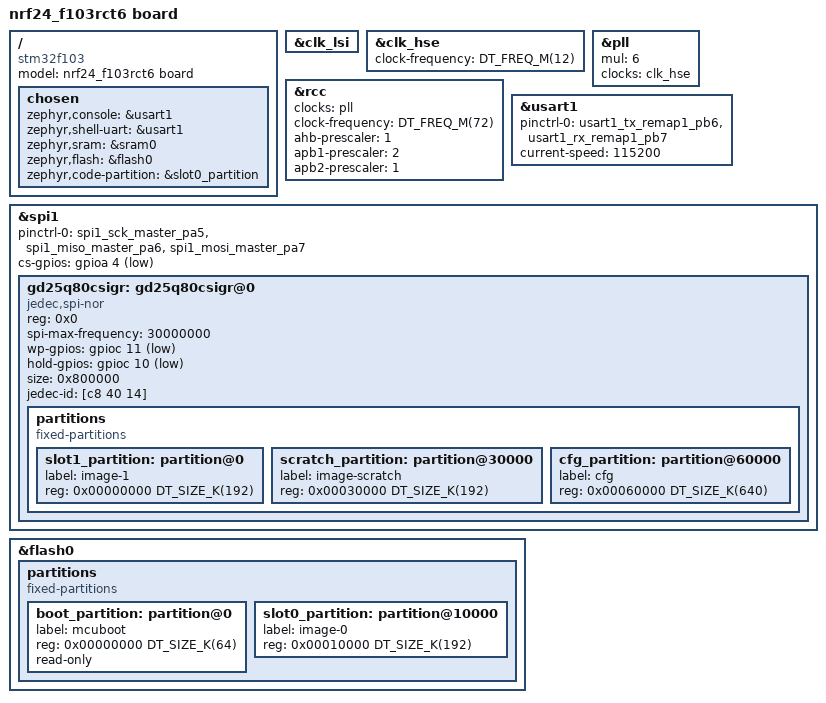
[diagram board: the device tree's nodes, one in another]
/*
 * Copyright (c) 2020 WuhanStudio
 *
 * SPDX-License-Identifier: Apache-2.0
 */

/dts-v1/;
#include <st/f1/stm32f103Xc.dtsi>
#include <st/f1/stm32f103r(c-d-e)tx-pinctrl.dtsi>

/ {
	model = "nrf24_f103rct6 board";
	compatible = "stm32f103";

	chosen {
		zephyr,console = &usart1;
		zephyr,shell-uart = &usart1;
		zephyr,sram = &sram0;
		zephyr,flash = &flash0;
		zephyr,code-partition = &slot0_partition;
	};
};

&clk_lsi {
	status = "okay";
};

&clk_hse {
	clock-frequency = <DT_FREQ_M(12)>;
	status = "okay";
};

&pll {
	mul = <6>;
	clocks = <&clk_hse>;
	status = "okay";
};

&rcc {
	clocks = <&pll>;
	clock-frequency = <DT_FREQ_M(72)>;
	ahb-prescaler = <1>;
	apb1-prescaler = <2>;
	apb2-prescaler = <1>;
	/* usbpre not set: USB clock = 72 / 1.5: 48MHz */
};

&usart1 {
	pinctrl-0 = <&usart1_tx_remap1_pb6 &usart1_rx_remap1_pb7>;
	pinctrl-names = "default";
	current-speed = <115200>;
	status = "okay";
};

&spi1 {
	pinctrl-0 = <&spi1_sck_master_pa5
		     &spi1_miso_master_pa6 &spi1_mosi_master_pa7>;
	pinctrl-names = "default";
	cs-gpios = <&gpioa 4 GPIO_ACTIVE_LOW>;
	status = "okay";
	gd25q80csigr: gd25q80csigr@0 {
		compatible = "jedec,spi-nor";
		reg = <0x0>;
		spi-max-frequency = <30000000>;
		wp-gpios = <&gpioc 11 GPIO_ACTIVE_LOW>;
		hold-gpios = <&gpioc 10 GPIO_ACTIVE_LOW>;
		size = <0x800000>;
		jedec-id = [c8 40 14];
		partitions {
			compatible = "fixed-partitions";
			#address-cells = <1>;
			#size-cells = <1>;

			slot1_partition: partition@0 {
				label = "image-1";
				reg = <0x00000000 DT_SIZE_K(192)>;
			};
			scratch_partition: partition@30000 {
				label = "image-scratch";
				reg = <0x00030000 DT_SIZE_K(192)>;
			};
			cfg_partition: partition@60000 {
				label = "cfg";
				reg = <0x00060000 DT_SIZE_K(640)>;
			};
		};
	};
};

&flash0 {
	partitions {
		compatible = "fixed-partitions";
		#address-cells = <1>;
		#size-cells = <1>;

		boot_partition: partition@0 {
			label = "mcuboot";
			reg = <0x00000000 DT_SIZE_K(64)>;
			read-only;
		};

		slot0_partition: partition@10000 {
			label = "image-0";
			reg = <0x00010000 DT_SIZE_K(192)>;
		};
	};
};

